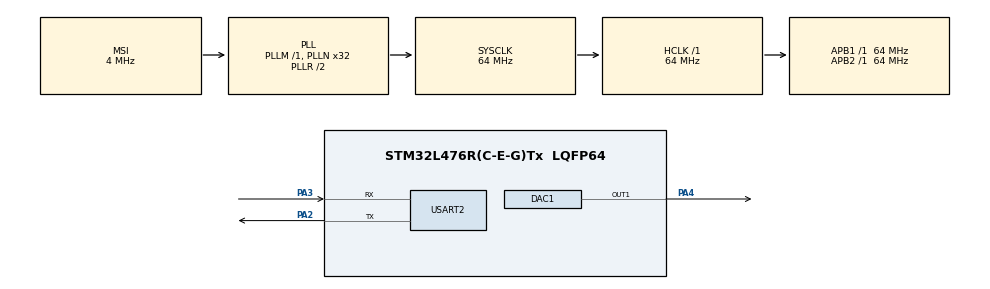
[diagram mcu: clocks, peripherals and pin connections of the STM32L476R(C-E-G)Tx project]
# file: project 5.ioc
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DAC1.DAC_Trigger-DAC_OUT1=DAC_TRIGGER_T2_TRGO
Dma.DAC_CH1.0.Direction=DMA_MEMORY_TO_PERIPH
Dma.DAC_CH1.0.Instance=DMA1_Channel3
Dma.DAC_CH1.0.MemDataAlignment=DMA_MDATAALIGN_WORD
Dma.DAC_CH1.0.MemInc=DMA_MINC_ENABLE
Dma.DAC_CH1.0.Mode=DMA_CIRCULAR
Dma.DAC_CH1.0.PeriphDataAlignment=DMA_PDATAALIGN_WORD
Dma.DAC_CH1.0.PeriphInc=DMA_PINC_DISABLE
Dma.DAC_CH1.0.Priority=DMA_PRIORITY_HIGH
Dma.Request0=DAC_CH1
Mcu.Family=STM32L4
Mcu.Name=STM32L476R(C-E-G)Tx
Mcu.Package=LQFP64
NVIC.DMA1_Channel3_IRQn=true\:0\:0\:false\:false\:true\:false\:true
NVIC.PriorityGroup=NVIC_PRIORITYGROUP_4
PA2.Mode=Asynchronous
PA2.Signal=USART2_TX
PA3.Mode=Asynchronous
PA3.Signal=USART2_RX
PA4.Signal=COMP_DAC11_group
ProjectManager.HeapSize=0x200
ProjectManager.StackSize=0x400
ProjectManager.TargetToolchain=STM32CubeIDE
RCC.AHBFreq_Value=64000000
RCC.APB1Freq_Value=64000000
RCC.APB1TimFreq_Value=64000000
RCC.APB2Freq_Value=64000000
RCC.APB2TimFreq_Value=64000000
RCC.CortexFreq_Value=64000000
RCC.HCLKFreq_Value=64000000
RCC.HSE_VALUE=8000000
RCC.HSI_VALUE=16000000
RCC.LSE_VALUE=32768
RCC.MSI_VALUE=4000000
RCC.PLLN=32
RCC.SYSCLKFreq_VALUE=64000000
RCC.SYSCLKSource=RCC_SYSCLKSOURCE_PLLCLK
RCC.VCOOutputFreq_Value=128000000
SH.COMP_DAC11_group.0=DAC1_OUT1,DAC_OUT1
TIM2.TIM_MasterOutputTrigger=TIM_TRGO_UPDATE
USART2.VirtualMode-Asynchronous=VM_ASYNC
VP_TIM2_VS_ClockSourceINT.Mode=Internal
board=custom

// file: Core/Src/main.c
/* USER CODE BEGIN Header */
/**
  ******************************************************************************
  * @file           : main.c
  * @brief          : Main program body
  ******************************************************************************
  * @attention
  *
  * <h2><center>&copy; Copyright (c) 2021 STMicroelectronics.
  * All rights reserved.</center></h2>
  *
  * This software component is licensed by ST under BSD 3-Clause license,
  * the "License"; You may not use this file except in compliance with the
  * License. You may obtain a copy of the License at:
  *                        opensource.org/licenses/BSD-3-Clause
  *
  ******************************************************************************
  */
/* USER CODE END Header */
#include "main.h"

DAC_HandleTypeDef hdac1;
DMA_HandleTypeDef hdma_dac_ch1;

TIM_HandleTypeDef htim2;

UART_HandleTypeDef huart2;

/* USER CODE BEGIN PV */
char type;
int frequency;
double min, max;
uint32_t dac_buffer[WAVE_BUFFER_SIZE] = {0};
char settings[BUFFER_SETTING_SIZE] = {0};
/* USER CODE END PV */

void SystemClock_Config(void);
static void MX_GPIO_Init(void);
static void MX_USART2_UART_Init(void);
static void MX_DMA_Init(void);
static void MX_DAC1_Init(void);
static void MX_TIM2_Init(void);

/* USER CODE BEGIN 0 */

/*
 * Verifies the user requested an acceptable signal
 * */
int check_input(){
	int flag = 1;
	if(!strchr("rstRST", type)){
		flag = 0;
	}
	if( (frequency < 10) || (frequency > 100000)){
		flag = 0;
	}
	if((min < 0.0) || (min >= max) || (min >= 3.3)){
		flag = 0;
	}
	if((max > 3.3) || (max <= min)){
		flag = 0;
	}
	return flag;
}

/* USER CODE END 0 */

int main(void)
{
  /* USER CODE BEGIN 1 */
  int DAC_MIN;
  int DAC_MAX;
  int samples;
  /* USER CODE END 1 */

  /* MCU Configuration--------------------------------------------------------*/

  /* Reset of all peripherals, Initializes the Flash interface and the Systick. */
  HAL_Init();

  /* Configure the system clock */
  SystemClock_Config();

  /* Initialize all configured peripherals */
  MX_GPIO_Init();
  MX_USART2_UART_Init();
  MX_DMA_Init();
  MX_DAC1_Init();
  MX_TIM2_Init();
  /* USER CODE BEGIN 2 */
  startup(huart2);
  /* USER CODE END 2 */

  /* Infinite loop */
  /* USER CODE BEGIN WHILE */
  while (1)
  {

	get_cmd(huart2, settings, BUFFER_SETTING_SIZE); //get the settings from the user
	parse(settings, &type, &frequency, &min, &max); //parses the user input and extracts the type, freq., and min/max of the wave
	if(!check_input()){ //checks for valid input
		USART_Write(huart2.Instance, (uint8_t *) "Invalid Input\r\n", strlen("Invalid Input\r\n"));
		continue;
	}
	sample(min, max, &DAC_MIN, &DAC_MAX, &samples); //calculates the number of samples and the min/max values for the dac to produce the proper min/max voltages
	update_timer(&htim2, &hdac1, frequency, samples);
	update_data(dac_buffer, type, samples, DAC_MIN, DAC_MAX);
	HAL_DAC_Start_DMA(&hdac1, DAC_CHANNEL_1, dac_buffer, samples, DAC_ALIGN_12B_R);
	HAL_TIM_Base_Start(&htim2);
    /* USER CODE END WHILE */

  }
}

void SystemClock_Config(void)
{
  RCC_OscInitTypeDef RCC_OscInitStruct = {0};
  RCC_ClkInitTypeDef RCC_ClkInitStruct = {0};

  /** Configure the main internal regulator output voltage
  */
  if (HAL_PWREx_ControlVoltageScaling(PWR_REGULATOR_VOLTAGE_SCALE1) != HAL_OK)
  {
    Error_Handler();
  }
  /** Initializes the RCC Oscillators according to the specified parameters
  * in the RCC_OscInitTypeDef structure.
  */
  RCC_OscInitStruct.OscillatorType = RCC_OSCILLATORTYPE_MSI;
  RCC_OscInitStruct.MSIState = RCC_MSI_ON;
  RCC_OscInitStruct.MSICalibrationValue = 0;
  RCC_OscInitStruct.MSIClockRange = RCC_MSIRANGE_6;
  RCC_OscInitStruct.PLL.PLLState = RCC_PLL_ON;
  RCC_OscInitStruct.PLL.PLLSource = RCC_PLLSOURCE_MSI;
  RCC_OscInitStruct.PLL.PLLM = 1;
  RCC_OscInitStruct.PLL.PLLN = 32;
  RCC_OscInitStruct.PLL.PLLP = RCC_PLLP_DIV7;
  RCC_OscInitStruct.PLL.PLLQ = RCC_PLLQ_DIV2;
  RCC_OscInitStruct.PLL.PLLR = RCC_PLLR_DIV2;
  if (HAL_RCC_OscConfig(&RCC_OscInitStruct) != HAL_OK)
  {
    Error_Handler();
  }
  /** Initializes the CPU, AHB and APB buses clocks
  */
  RCC_ClkInitStruct.ClockType = RCC_CLOCKTYPE_HCLK|RCC_CLOCKTYPE_SYSCLK
                              |RCC_CLOCKTYPE_PCLK1|RCC_CLOCKTYPE_PCLK2;
  RCC_ClkInitStruct.SYSCLKSource = RCC_SYSCLKSOURCE_PLLCLK;
  RCC_ClkInitStruct.AHBCLKDivider = RCC_SYSCLK_DIV1;
  RCC_ClkInitStruct.APB1CLKDivider = RCC_HCLK_DIV1;
  RCC_ClkInitStruct.APB2CLKDivider = RCC_HCLK_DIV1;

  if (HAL_RCC_ClockConfig(&RCC_ClkInitStruct, FLASH_LATENCY_3) != HAL_OK)
  {
    Error_Handler();
  }
}

static void MX_DAC1_Init(void)
{

  DAC_ChannelConfTypeDef sConfig = {0};

  /** DAC Initialization
  */
  hdac1.Instance = DAC1;
  if (HAL_DAC_Init(&hdac1) != HAL_OK)
  {
    Error_Handler();
  }
  /** DAC channel OUT1 config
  */
  sConfig.DAC_SampleAndHold = DAC_SAMPLEANDHOLD_DISABLE;
  sConfig.DAC_Trigger = DAC_TRIGGER_T2_TRGO;
  sConfig.DAC_OutputBuffer = DAC_OUTPUTBUFFER_ENABLE;
  sConfig.DAC_ConnectOnChipPeripheral = DAC_CHIPCONNECT_DISABLE;
  sConfig.DAC_UserTrimming = DAC_TRIMMING_FACTORY;
  if (HAL_DAC_ConfigChannel(&hdac1, &sConfig, DAC_CHANNEL_1) != HAL_OK)
  {
    Error_Handler();
  }

}

static void MX_TIM2_Init(void)
{

  TIM_ClockConfigTypeDef sClockSourceConfig = {0};
  TIM_MasterConfigTypeDef sMasterConfig = {0};

  htim2.Instance = TIM2;
  htim2.Init.Prescaler = 0;
  htim2.Init.CounterMode = TIM_COUNTERMODE_UP;
  htim2.Init.Period = 4294967295;
  htim2.Init.ClockDivision = TIM_CLOCKDIVISION_DIV1;
  htim2.Init.AutoReloadPreload = TIM_AUTORELOAD_PRELOAD_DISABLE;
  if (HAL_TIM_Base_Init(&htim2) != HAL_OK)
  {
    Error_Handler();
  }
  sClockSourceConfig.ClockSource = TIM_CLOCKSOURCE_INTERNAL;
  if (HAL_TIM_ConfigClockSource(&htim2, &sClockSourceConfig) != HAL_OK)
  {
    Error_Handler();
  }
  sMasterConfig.MasterOutputTrigger = TIM_TRGO_UPDATE;
  sMasterConfig.MasterSlaveMode = TIM_MASTERSLAVEMODE_DISABLE;
  if (HAL_TIMEx_MasterConfigSynchronization(&htim2, &sMasterConfig) != HAL_OK)
  {
    Error_Handler();
  }

}

static void MX_USART2_UART_Init(void)
{

  huart2.Instance = USART2;
  huart2.Init.BaudRate = 115200;
  huart2.Init.WordLength = UART_WORDLENGTH_8B;
  huart2.Init.StopBits = UART_STOPBITS_1;
  huart2.Init.Parity = UART_PARITY_NONE;
  huart2.Init.Mode = UART_MODE_TX_RX;
  huart2.Init.HwFlowCtl = UART_HWCONTROL_NONE;
  huart2.Init.OverSampling = UART_OVERSAMPLING_16;
  huart2.Init.OneBitSampling = UART_ONE_BIT_SAMPLE_DISABLE;
  huart2.AdvancedInit.AdvFeatureInit = UART_ADVFEATURE_NO_INIT;
  if (HAL_UART_Init(&huart2) != HAL_OK)
  {
    Error_Handler();
  }

}

static void MX_DMA_Init(void)
{

  /* DMA controller clock enable */
  __HAL_RCC_DMA1_CLK_ENABLE();

  /* DMA interrupt init */
  /* DMA1_Channel3_IRQn interrupt configuration */
  HAL_NVIC_SetPriority(DMA1_Channel3_IRQn, 0, 0);
  HAL_NVIC_EnableIRQ(DMA1_Channel3_IRQn);

}

static void MX_GPIO_Init(void)
{

  /* GPIO Ports Clock Enable */
  __HAL_RCC_GPIOA_CLK_ENABLE();

}

void Error_Handler(void)
{
  __disable_irq();
  while (1)
  {
  }
}

/************************ (C) COPYRIGHT STMicroelectronics *****END OF FILE****/
